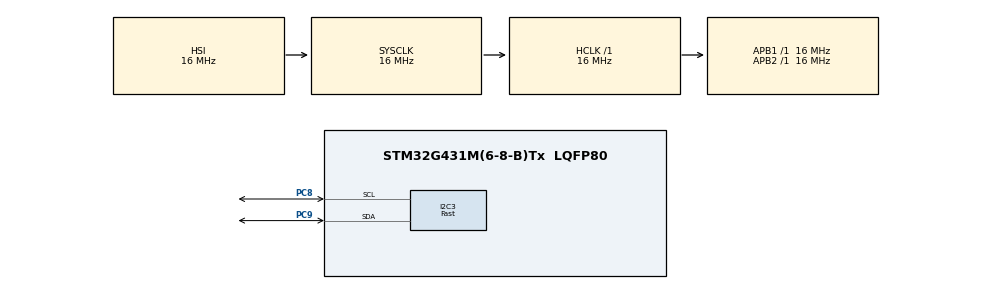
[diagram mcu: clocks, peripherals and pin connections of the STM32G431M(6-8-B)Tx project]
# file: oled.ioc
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I2C3.I2C_Speed_Mode=I2C_Fast
I2C3.Timing=0x0010061A
Mcu.Family=STM32G4
Mcu.Name=STM32G431M(6-8-B)Tx
Mcu.Package=LQFP80
NVIC.I2C3_ER_IRQn=true\:0\:0\:false\:false\:true\:true\:true\:true
NVIC.I2C3_EV_IRQn=true\:0\:0\:false\:false\:true\:true\:true\:true
NVIC.PriorityGroup=NVIC_PRIORITYGROUP_4
PA13.Mode=Serial_Wire
PA13.Signal=SYS_JTMS-SWDIO
PA14.Mode=Serial_Wire
PA14.Signal=SYS_JTCK-SWCLK
PC8.Mode=I2C
PC8.Signal=I2C3_SCL
PC9.Mode=I2C
PC9.Signal=I2C3_SDA
ProjectManager.HeapSize=0x200
ProjectManager.StackSize=0x400
ProjectManager.TargetToolchain=STM32CubeIDE
RCC.AHBFreq_Value=16000000
RCC.APB1Freq_Value=16000000
RCC.APB1TimFreq_Value=16000000
RCC.APB2Freq_Value=16000000
RCC.APB2TimFreq_Value=16000000
RCC.CortexFreq_Value=16000000
RCC.EXTERNAL_CLOCK_VALUE=12288000
RCC.HCLKFreq_Value=16000000
RCC.HSE_VALUE=8000000
RCC.HSI48_VALUE=48000000
RCC.HSI_VALUE=16000000
RCC.LSE_VALUE=32768
RCC.SYSCLKFreq_VALUE=16000000
RCC.USBFreq_Value=64000000
RCC.VCOOutputFreq_Value=128000000
VP_SYS_VS_DBSignals.Mode=DisableDeadBatterySignals
board=custom

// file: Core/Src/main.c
/* USER CODE BEGIN Header */
/**
  ******************************************************************************
  * @file           : main.c
  * @brief          : Main program body
  ******************************************************************************
  * @attention
  *
  * Copyright (c) 2023 STMicroelectronics.
  * All rights reserved.
  *
  * This software is licensed under terms that can be found in the LICENSE file
  * in the root directory of this software component.
  * If no LICENSE file comes with this software, it is provided AS-IS.
  *
  ******************************************************************************
  */
/* USER CODE END Header */
#include "main.h"

/* USER CODE BEGIN Includes */
#include <stdio.h>
#include <stdlib.h>
#include <string.h>
#include "ssd1306.h"
#include "fonts.h"
#include "test.h"
#include "bitmap.h"
/* USER CODE END Includes */

I2C_HandleTypeDef hi2c3;
char buffer[10]={'P','A','V','A','N','\0'};
char symbol[10]={0};
uint16_t CO_2=10;
uint16_t PM_2_5=10;
uint16_t PM_10=10;
uint16_t Humidity=10;
uint16_t Temp=10;
uint16_t Light_intensity=10;

void SystemClock_Config(void);
static void MX_GPIO_Init(void);
static void MX_I2C3_Init(void);

int main(void)
{

  /* MCU Configuration--------------------------------------------------------*/

  /* Reset of all peripherals, Initializes the Flash interface and the Systick. */
  HAL_Init();

  /* Configure the system clock */
  SystemClock_Config();

  /* Initialize all configured peripherals */
  MX_GPIO_Init();
  MX_I2C3_Init();
  /* USER CODE BEGIN 2 */
  //sprintf(buffer,"%d",CO_2);
  SSD1306_Init (); // initialize the display

  SSD1306_DrawBitmap(0,0,ganesha,128,64,1);
  SSD1306_UpdateScreen();
 HAL_Delay(2000);
 SSD1306_Clear ();

 SSD1306_DrawBitmap(0,0,Temperature,128,64,1);
 SSD1306_DrawBitmap(0,0,degree_centigrade,128,64,1);
 HAL_Delay(2000);
 SSD1306_GotoXY (70,10); // goto 10, 10
 SSD1306_Puts ("80", &Font_16x26, 1);
//
//  SSD1306_UpdateScreen();
//  HAL_Delay(2000);
//  SSD1306_Clear ();
//  SSD1306_DrawBitmap(0,0,humidity,128,64,1);
//  SSD1306_DrawBitmap(0,0,percentage,128,64,1);
//  SSD1306_GotoXY (50,30); // goto 10, 10
//  SSD1306_Puts ("40", &Font_16x26, 1);
//
//  SSD1306_UpdateScreen();
//  HAL_Delay(2000);
//  SSD1306_Clear ();
//
//  SSD1306_DrawBitmap(0,0,PM2,128,64,1);
//  SSD1306_DrawBitmap(0,0,micro_gram_per_cubic_meter,128,64,1);
//  SSD1306_GotoXY (82,10); // goto 10, 10
//  SSD1306_Puts ("50", &Font_16x26, 1);
//  SSD1306_GotoXY (120,30);
//  //SSD1306_Puts ("µg/m³", &Font_7x10, 1);
//  SSD1306_UpdateScreen();
//  HAL_Delay(2000);
//  SSD1306_Clear ();
//  SSD1306_DrawBitmap(0,0,PM10,128,64,1);
//  SSD1306_DrawBitmap(0,0,micro_gram_per_cubic_meter,128,64,1);
//  SSD1306_GotoXY (82,10); // goto 10, 10
//  SSD1306_Puts ("60", &Font_16x26, 1);
//  SSD1306_GotoXY (120,30);
//  //SSD1306_Puts ("µg/m³", &Font_7x10, 1);
//  SSD1306_UpdateScreen();
//  HAL_Delay(2000);
//  SSD1306_Clear ();
//  SSD1306_DrawBitmap(0,0,CO2,128,64,1);
//  SSD1306_DrawBitmap(0,0,ppm,128,64,1);
//  SSD1306_GotoXY (82,10); // goto 10, 10
//  SSD1306_Puts (buffer, &Font_16x26, 1);
//  SSD1306_GotoXY (120,30);
//  //SSD1306_Puts ("ppm", &Font_7x10, 1);
//  SSD1306_UpdateScreen();
//  HAL_Delay(2000);
//  SSD1306_Clear ();
//  SSD1306_DrawBitmap(0,0,Light_Intensity,128,64,1);
//  SSD1306_GotoXY (82,10); // goto 10, 10
//  SSD1306_Puts (buffer, &Font_16x26, 1);
//  SSD1306_GotoXY (120,30);
//  //SSD1306_Puts ("ppm", &Font_7x10, 1);
//  SSD1306_UpdateScreen();
//  HAL_Delay(2000);

  //SSD1306_DrawLine(64, 0, 64 , 64, 0x01);
  //SSD1306_DrawLine(0, 32, 128 , 32, 0x01);
  //SSD1306_DrawRectangle(0, 0, 128, 64, 0x01);
  //SSD1306_UpdateScreen();
  //HAL_Delay(2000);
  //SSD1306_GotoXY (5,5); // goto 10, 10
  //SSD1306_Puts ("CO2=0.22", &Font_7x10, 1);
  //SSD1306_GotoXY (5, 37);
  //SSD1306_Puts ("CO=0.34", &Font_7x10, 1);
  //SSD1306_GotoXY (75,5); // goto 10, 10
  //SSD1306_Puts ("CO2=0.22", &Font_7x10, 1);
  //SSD1306_GotoXY (75, 37);
  //SSD1306_Puts ("CO=0.34", &Font_7x10, 1); //Font_7x10 Font_11x18
  //SSD1306_UpdateScreen(); // update scree
  //SSD1306_Clear ();
  /* USER CODE END 2 */

  /* Infinite loop */
  while (1)
  {

  }
}

void SystemClock_Config(void)
{
  RCC_OscInitTypeDef RCC_OscInitStruct = {0};
  RCC_ClkInitTypeDef RCC_ClkInitStruct = {0};

  /** Configure the main internal regulator output voltage
  */
  HAL_PWREx_ControlVoltageScaling(PWR_REGULATOR_VOLTAGE_SCALE1);

  /** Initializes the RCC Oscillators according to the specified parameters
  * in the RCC_OscInitTypeDef structure.
  */
  RCC_OscInitStruct.OscillatorType = RCC_OSCILLATORTYPE_HSI;
  RCC_OscInitStruct.HSIState = RCC_HSI_ON;
  RCC_OscInitStruct.HSICalibrationValue = RCC_HSICALIBRATION_DEFAULT;
  RCC_OscInitStruct.PLL.PLLState = RCC_PLL_NONE;
  if (HAL_RCC_OscConfig(&RCC_OscInitStruct) != HAL_OK)
  {
    Error_Handler();
  }

  /** Initializes the CPU, AHB and APB buses clocks
  */
  RCC_ClkInitStruct.ClockType = RCC_CLOCKTYPE_HCLK|RCC_CLOCKTYPE_SYSCLK
                              |RCC_CLOCKTYPE_PCLK1|RCC_CLOCKTYPE_PCLK2;
  RCC_ClkInitStruct.SYSCLKSource = RCC_SYSCLKSOURCE_HSI;
  RCC_ClkInitStruct.AHBCLKDivider = RCC_SYSCLK_DIV1;
  RCC_ClkInitStruct.APB1CLKDivider = RCC_HCLK_DIV1;
  RCC_ClkInitStruct.APB2CLKDivider = RCC_HCLK_DIV1;

  if (HAL_RCC_ClockConfig(&RCC_ClkInitStruct, FLASH_LATENCY_0) != HAL_OK)
  {
    Error_Handler();
  }
}

static void MX_I2C3_Init(void)
{

  hi2c3.Instance = I2C3;
  hi2c3.Init.Timing = 0x0010061A;
  hi2c3.Init.OwnAddress1 = 0;
  hi2c3.Init.AddressingMode = I2C_ADDRESSINGMODE_7BIT;
  hi2c3.Init.DualAddressMode = I2C_DUALADDRESS_DISABLE;
  hi2c3.Init.OwnAddress2 = 0;
  hi2c3.Init.OwnAddress2Masks = I2C_OA2_NOMASK;
  hi2c3.Init.GeneralCallMode = I2C_GENERALCALL_DISABLE;
  hi2c3.Init.NoStretchMode = I2C_NOSTRETCH_DISABLE;
  if (HAL_I2C_Init(&hi2c3) != HAL_OK)
  {
    Error_Handler();
  }

  /** Configure Analogue filter
  */
  if (HAL_I2CEx_ConfigAnalogFilter(&hi2c3, I2C_ANALOGFILTER_ENABLE) != HAL_OK)
  {
    Error_Handler();
  }

  /** Configure Digital filter
  */
  if (HAL_I2CEx_ConfigDigitalFilter(&hi2c3, 0) != HAL_OK)
  {
    Error_Handler();
  }

}

static void MX_GPIO_Init(void)
{

  /* GPIO Ports Clock Enable */
  __HAL_RCC_GPIOC_CLK_ENABLE();
  __HAL_RCC_GPIOA_CLK_ENABLE();

}

void Error_Handler(void)
{
  __disable_irq();
  while (1)
  {
  }
}
